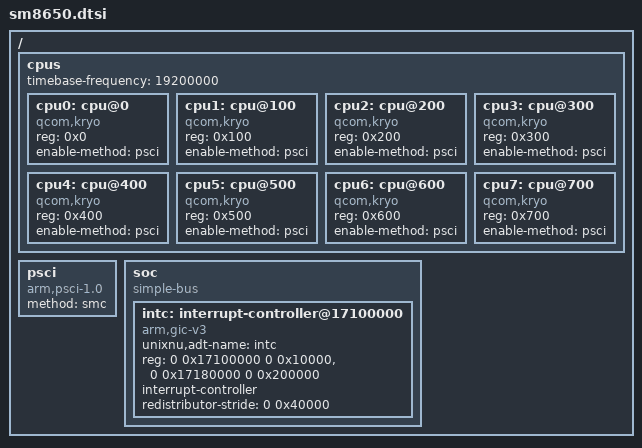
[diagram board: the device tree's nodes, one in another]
// SPDX-License-Identifier: BSD-2-Clause-Patent
// Resource slice from the existing K80 ADT generator and SMP identity policy.
/ {
    #address-cells = <2>;
    #size-cells = <2>;
    cpus {
        #address-cells = <1>;
        #size-cells = <0>;
        timebase-frequency = <19200000>;
        cpu0: cpu@0 { device_type = "cpu"; compatible = "qcom,kryo"; reg = <0x0>; enable-method = "psci"; };
        cpu1: cpu@100 { device_type = "cpu"; compatible = "qcom,kryo"; reg = <0x100>; enable-method = "psci"; };
        cpu2: cpu@200 { device_type = "cpu"; compatible = "qcom,kryo"; reg = <0x200>; enable-method = "psci"; };
        cpu3: cpu@300 { device_type = "cpu"; compatible = "qcom,kryo"; reg = <0x300>; enable-method = "psci"; };
        cpu4: cpu@400 { device_type = "cpu"; compatible = "qcom,kryo"; reg = <0x400>; enable-method = "psci"; };
        cpu5: cpu@500 { device_type = "cpu"; compatible = "qcom,kryo"; reg = <0x500>; enable-method = "psci"; };
        cpu6: cpu@600 { device_type = "cpu"; compatible = "qcom,kryo"; reg = <0x600>; enable-method = "psci"; };
        cpu7: cpu@700 { device_type = "cpu"; compatible = "qcom,kryo"; reg = <0x700>; enable-method = "psci"; };
    };
    psci { compatible = "arm,psci-1.0"; method = "smc"; };
    soc {
        compatible = "simple-bus";
        #address-cells = <2>;
        #size-cells = <2>;
        ranges;
        intc: interrupt-controller@17100000 {
            compatible = "arm,gic-v3";
            unixnu,adt-name = "intc";
            reg = <0 0x17100000 0 0x10000>, <0 0x17180000 0 0x200000>;
            interrupt-controller;
            #interrupt-cells = <3>;
            #address-cells = <0>;
            redistributor-stride = <0 0x40000>;
        };
    };
};
